VERSION "0.2"

NS_ :

BS_ :

BU_ : BMS_LV DIAG_TOOL SB_FRONT TLB_BAT TPMS IMU DASH DSPACE EXTRA_NODE SB_REAR SCANNER

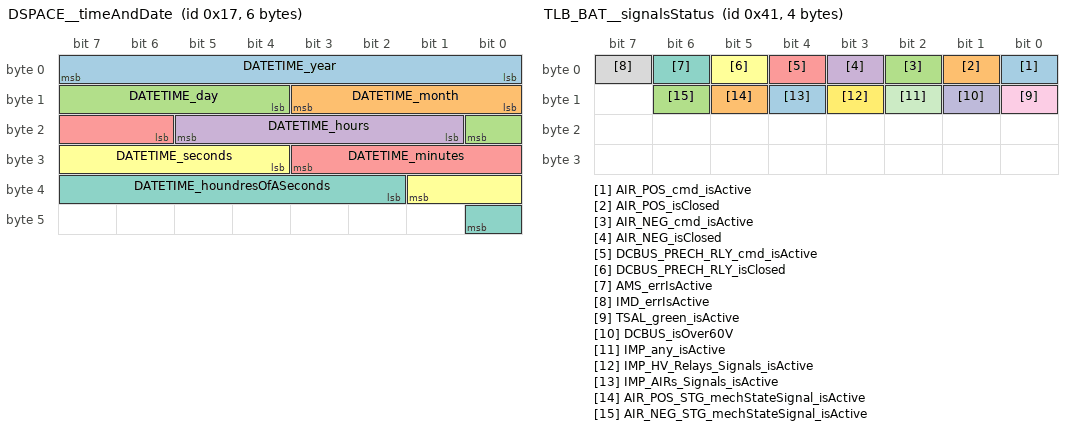
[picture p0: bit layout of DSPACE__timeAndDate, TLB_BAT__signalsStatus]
BO_ 23 DSPACE__timeAndDate: 6 DSPACE
	SG_ DATETIME_year : 0|8@1+ (1,0) [0|255] "" DASH,SB_FRONT,SB_REAR,SCANNER,TLB_BAT,BMS_LV
	SG_ DATETIME_month : 8|4@1+ (1,0) [0|11] "" DASH,SB_FRONT,SB_REAR,SCANNER,TLB_BAT,BMS_LV
	SG_ DATETIME_day : 12|5@1+ (1,0) [1|31] "" DASH,SB_FRONT,SB_REAR,SCANNER,TLB_BAT,BMS_LV
	SG_ DATETIME_hours : 17|5@1+ (1,0) [0|23] "h" DASH,SB_FRONT,SB_REAR,SCANNER,TLB_BAT,BMS_LV
	SG_ DATETIME_minutes : 22|6@1+ (1,0) [0|59] "min" DASH,SB_FRONT,SB_REAR,SCANNER,TLB_BAT,BMS_LV
	SG_ DATETIME_seconds : 28|6@1+ (1,0) [0|59] "sec" DASH,SB_FRONT,SB_REAR,SCANNER,TLB_BAT,BMS_LV
	SG_ DATETIME_houndresOfASeconds : 34|7@1+ (1,0) [0|99] "sec" DASH,SB_FRONT,SB_REAR,SCANNER,TLB_BAT,BMS_LV

BO_ 65 TLB_BAT__signalsStatus: 4 TLB_BAT
	SG_ AIR_POS_cmd_isActive : 0|1@1+ (1,0) [0|1] "" DSPACE,SCANNER
	SG_ AIR_POS_isClosed : 1|1@1+ (1,0) [0|1] "" DSPACE,SCANNER
	SG_ AIR_NEG_cmd_isActive : 2|1@1+ (1,0) [0|1] "" DSPACE,SCANNER
	SG_ AIR_NEG_isClosed : 3|1@1+ (1,0) [0|1] "" DSPACE,SCANNER
	SG_ DCBUS_PRECH_RLY_cmd_isActive : 4|1@1+ (1,0) [0|1] "" DSPACE,SCANNER
	SG_ DCBUS_PRECH_RLY_isClosed : 5|1@1+ (1,0) [0|1] "" DSPACE,SCANNER
	SG_ AMS_errIsActive : 6|1@1+ (1,0) [0|1] "" DSPACE,SCANNER
	SG_ IMD_errIsActive : 7|1@1+ (1,0) [0|1] "" DSPACE,SCANNER
	SG_ TSAL_green_isActive : 8|1@1+ (1,0) [0|1] "" DSPACE,SCANNER
	SG_ DCBUS_isOver60V : 9|1@1+ (1,0) [0|1] "" DSPACE,SCANNER
	SG_ IMP_any_isActive : 10|1@1+ (1,0) [0|1] "" DSPACE,SCANNER
	SG_ IMP_HV_Relays_Signals_isActive : 11|1@1+ (1,0) [0|1] "" DSPACE,SCANNER
	SG_ IMP_AIRs_Signals_isActive : 12|1@1+ (1,0) [0|1] "" DSPACE,SCANNER
	SG_ AIR_POS_STG_mechStateSignal_isActive : 13|1@1+ (1,0) [0|1] "" DSPACE,SCANNER
	SG_ AIR_NEG_STG_mechStateSignal_isActive : 14|1@1+ (1,0) [0|1] "" DSPACE,SCANNER

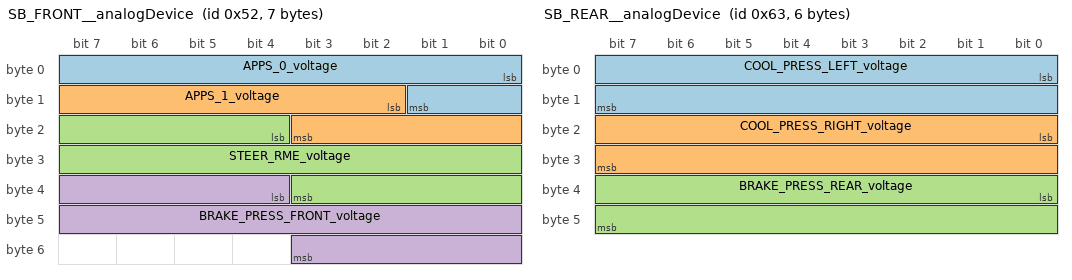
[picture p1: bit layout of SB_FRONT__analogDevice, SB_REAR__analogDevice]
BO_ 82 SB_FRONT__analogDevice: 7 SB_FRONT
	SG_ APPS_0_voltage : 0|10@1+ (1,0) [0|65535] "mV" DSPACE,SCANNER
	SG_ APPS_1_voltage : 10|10@1+ (1,0) [0|65535] "mV" DSPACE,SCANNER
	SG_ STEER_RME_voltage : 20|16@1+ (1,0) [0|65535] "mV" DSPACE,SCANNER
	SG_ BRAKE_PRESS_FRONT_voltage : 36|16@1+ (1,0) [0|65535] "mV" DSPACE,SCANNER

BO_ 99 SB_REAR__analogDevice: 6 SB_REAR
	SG_ COOL_PRESS_LEFT_voltage : 0|16@1+ (1,0) [0|65535] "mV" DSPACE,SCANNER
	SG_ COOL_PRESS_RIGHT_voltage : 16|16@1+ (1,0) [0|65535] "mV" DSPACE,SCANNER
	SG_ BRAKE_PRESS_REAR_voltage : 32|16@1+ (1,0) [0|65535] "mV" DSPACE,SCANNER

BO_ 115 SB_REAR__criticalPeripherals: 1 SB_REAR
	SG_ DISCHARGE_isOpen : 0|1@1+ (1,0) [0|1] "" DSPACE,SCANNER
	SG_ BSPD_hasError : 1|1@1+ (1,0) [0|1] "" DSPACE,SCANNER

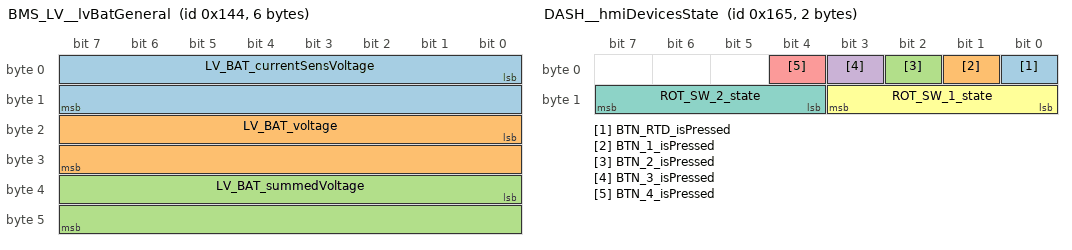
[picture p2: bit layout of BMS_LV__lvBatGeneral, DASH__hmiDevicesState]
BO_ 324 BMS_LV__lvBatGeneral: 6 BMS_LV
	SG_ LV_BAT_currentSensVoltage : 0|16@1+ (0.076,0) [0|4980.66] "mV" DSPACE,SCANNER
	SG_ LV_BAT_voltage : 16|16@1+ (0.267,14000) [0|17497.845] "mV" DSPACE,SCANNER
	SG_ LV_BAT_summedVoltage : 32|16@1+ (0.267,14000) [0|17497.845] "mV" DSPACE,SCANNER

BO_ 357 DASH__hmiDevicesState: 2 DASH
	SG_ BTN_RTD_isPressed : 0|1@1+ (1,0) [0|255] "" DSPACE,SCANNER
	SG_ BTN_1_isPressed : 1|1@1+ (1,0) [0|1] "" DSPACE,SCANNER
	SG_ BTN_2_isPressed : 2|1@1+ (1,0) [0|1] "" DSPACE,SCANNER
	SG_ BTN_3_isPressed : 3|1@1+ (1,0) [0|1] "" DSPACE,SCANNER
	SG_ BTN_4_isPressed : 4|1@1+ (1,0) [0|1] "" DSPACE,SCANNER
	SG_ ROT_SW_1_state : 8|4@1+ (1,0) [0|9] "" DSPACE,SCANNER
	SG_ ROT_SW_2_state : 12|4@1+ (1,0) [0|9] "" DSPACE,SCANNER

BO_ 388 SBG_ECAN_MSG_GPS2_POS_INFO: 8 IMU
	SG_ TIME_STAMP : 0|32@1+ (1,0) [0|4294970000] "usec" SCANNER
	SG_ STATUS : 32|32@1+ (1,0) [0|4294970000] "" SCANNER

BO_ 389 SBG_ECAN_MSG_GPS2_POS: 8 IMU
	SG_ LATITUDE : 0|32@1- (0.0000001,0) [-214.7483648|214.7483647] "deg" SCANNER
	SG_ LONGITUDE : 32|32@1- (0.0000001,0) [-214.7483648|214.7483647] "deg" SCANNER

BO_ 392 SBG_ECAN_MSG_GPS2_HDT_INFO: 6 IMU
	SG_ TIME_STAMP : 0|32@1+ (1,0) [0|4294970000] "usec" SCANNER
	SG_ STATUS : 32|16@1+ (1,0) [0|65535] "" SCANNER

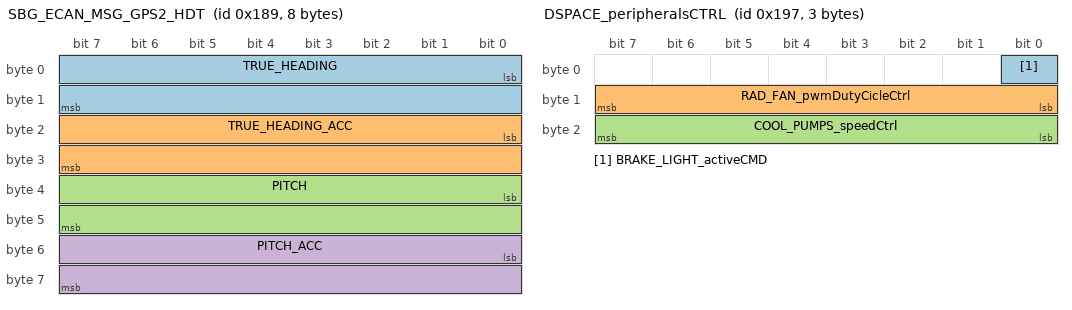
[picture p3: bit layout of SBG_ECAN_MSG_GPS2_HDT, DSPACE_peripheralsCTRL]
BO_ 393 SBG_ECAN_MSG_GPS2_HDT: 8 IMU
	SG_ TRUE_HEADING : 0|16@1+ (0.01,0) [0|655.35] "deg" SCANNER
	SG_ TRUE_HEADING_ACC : 16|16@1+ (0.01,0) [0|655.35] "deg" SCANNER
	SG_ PITCH : 32|16@1- (0.01,0) [-327.68|327.67] "deg" SCANNER
	SG_ PITCH_ACC : 48|16@1+ (0.01,0) [0|655.35] "deg" SCANNER

BO_ 407 DSPACE_peripheralsCTRL: 3 DSPACE
	SG_ BRAKE_LIGHT_activeCMD : 0|1@1+ (1,0) [0|1] "" DASH,SB_REAR,SCANNER
	SG_ RAD_FAN_pwmDutyCicleCtrl : 8|8@1+ (1,0) [0|100] "%" DASH,SB_REAR,SCANNER
	SG_ COOL_PUMPS_speedCtrl : 16|8@1+ (1,0) [0|100] "%" DASH,SB_REAR,SCANNER

BO_ 512 SBG_ECAN_MSG_EVENT_INFO_A: 8 IMU
	SG_ TIME_STAMP : 0|32@1+ (1,0) [0|4294970000] "usec" Vector__XXX
	SG_ STATUS : 32|16@1+ (1,0) [0|65535] "" Vector__XXX

BO_ 646 DIAG_TOOL__xcpTxBMS_LV: 8 DIAG_TOOL
	SG_ xcp_payload : 0|64@1+ (1,0) [0|0] "" BMS_LV

BO_ 662 DIAG_TOOL__xcpTxDASH: 8 DIAG_TOOL
	SG_ xcp_payload : 0|64@1+ (1,0) [0|0] "" DASH

BO_ 678 DIAG_TOOL__xcpTxSB_REAR: 8 DIAG_TOOL
	SG_ xcp_payload : 0|64@1+ (1,0) [0|0] "" SB_REAR

BO_ 694 DIAG_TOOL__xcpTxSB_FRONT: 8 DIAG_TOOL
	SG_ xcp_payload : 0|64@1+ (1,0) [0|0] "" SB_FRONT

BO_ 710 DIAG_TOOL__xcpTxSCANNER: 8 DIAG_TOOL
	SG_ xcp_payload : 0|64@1+ (1,0) [0|0] "" SCANNER

BO_ 726 DIAG_TOOL__xcpTxTLB_BAT: 8 DIAG_TOOL
	SG_ xcp_payload : 0|64@1+ (1,0) [0|0] "" TLB_BAT

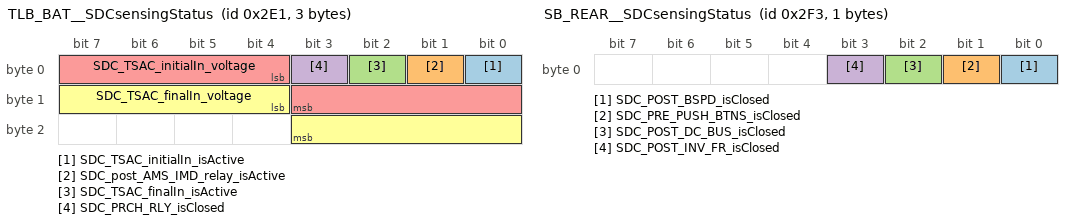
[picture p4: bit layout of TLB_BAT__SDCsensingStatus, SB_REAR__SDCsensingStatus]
BO_ 737 TLB_BAT__SDCsensingStatus: 3 TLB_BAT
	SG_ SDC_TSAC_initialIn_isActive : 0|1@1+ (1,0) [0|1] "" DSPACE,SCANNER
	SG_ SDC_post_AMS_IMD_relay_isActive : 1|1@1+ (1,0) [0|1] "" DSPACE,SCANNER
	SG_ SDC_TSAC_finalIn_isActive : 2|1@1+ (1,0) [0|1] "" DSPACE,SCANNER
	SG_ SDC_PRCH_RLY_isClosed : 3|1@1+ (1,0) [0|1] "" DSPACE,SCANNER
	SG_ SDC_TSAC_initialIn_voltage : 4|8@1+ (0.177,0) [0|255] "V" DSPACE,SCANNER
	SG_ SDC_TSAC_finalIn_voltage : 12|8@1+ (0.177,0) [0|255] "V" DSPACE,SCANNER

BO_ 755 SB_REAR__SDCsensingStatus: 1 SB_REAR
	SG_ SDC_POST_BSPD_isClosed : 0|1@1+ (1,0) [0|1] "" DSPACE,SCANNER
	SG_ SDC_PRE_PUSH_BTNS_isClosed : 1|1@1+ (1,0) [0|1] "" DSPACE,SCANNER
	SG_ SDC_POST_DC_BUS_isClosed : 2|1@1+ (1,0) [0|1] "" DSPACE,SCANNER
	SG_ SDC_POST_INV_FR_isClosed : 3|1@1+ (1,0) [0|1] "" DSPACE,SCANNER

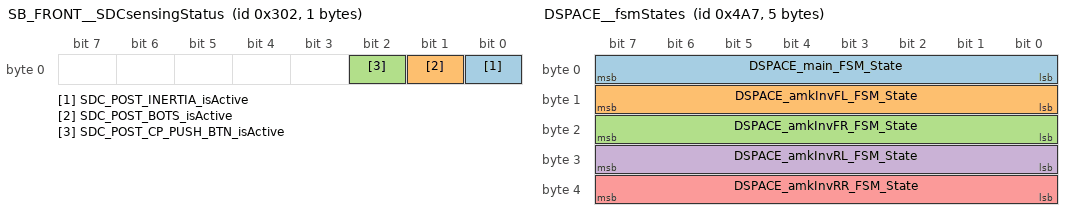
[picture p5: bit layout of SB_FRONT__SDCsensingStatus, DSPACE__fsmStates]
BO_ 770 SB_FRONT__SDCsensingStatus: 1 SB_FRONT
	SG_ SDC_POST_INERTIA_isActive : 0|1@1+ (1,0) [0|1] "" DSPACE,SCANNER
	SG_ SDC_POST_BOTS_isActive : 1|1@1+ (1,0) [0|1] "" DSPACE,SCANNER
	SG_ SDC_POST_CP_PUSH_BTN_isActive : 2|1@1+ (1,0) [0|1] "" DSPACE,SCANNER

BO_ 802 SB_FRONT__potentiometer: 4 SB_FRONT
	SG_ LPPS_DAMPER_FL_voltage : 0|16@1+ (1,0) [0|65535] "mV" DSPACE,SCANNER
	SG_ LPPS_DAMPER_FR_voltage : 16|16@1+ (1,0) [0|65535] "mV" DSPACE,SCANNER

BO_ 819 SB_REAR__potentiometer: 4 SB_REAR
	SG_ LPPS_DAMPER_RL_voltage : 0|16@1+ (1,0) [0|65535] "mV" DSPACE,SCANNER
	SG_ LPPS_DAMPER_RR_voltage : 16|16@1+ (1,0) [0|65535] "mV" DSPACE,SCANNER

BO_ 1121 TLB_BAT__xcpTx: 8 TLB_BAT
	SG_ xcp_payload : 0|64@1+ (1,0) [0|0] "" DIAG_TOOL

BO_ 1122 SB_FRONT__xcpTx: 8 SB_FRONT
	SG_ xcp_payload : 0|64@1+ (1,0) [0|0] "" DIAG_TOOL

BO_ 1123 SB_REAR__xcpTx: 8 SB_REAR
	SG_ xcp_payload : 0|64@1+ (1,0) [0|0] "" DIAG_TOOL

BO_ 1124 BMS_LV__xcpTx: 8 BMS_LV
	SG_ xcp_payload : 0|64@1+ (1,0) [0|0] "" DIAG_TOOL

BO_ 1125 DASH__xcpTx: 8 DASH
	SG_ xcp_payload : 0|64@1+ (1,0) [0|0] "" DIAG_TOOL

BO_ 1129 SCANNER__xcpTx: 8 SCANNER
	SG_ xcp_payload : 0|64@1+ (1,0) [0|0] "" DIAG_TOOL

BO_ 1175 DSPACE__signals: 1 DSPACE
	SG_ HVBAT_soc : 0|8@1+ (1,0) [100|0] "%" DASH,SCANNER

BO_ 1191 DSPACE__fsmStates: 5 DSPACE
	SG_ DSPACE_main_FSM_State : 0|8@1- (1,0) [-1|5] "" DASH,SCANNER
	SG_ DSPACE_amkInvFL_FSM_State : 8|8@1- (1,0) [0|6] "" DASH,SCANNER
	SG_ DSPACE_amkInvFR_FSM_State : 16|8@1- (1,0) [0|6] "" DASH,SCANNER
	SG_ DSPACE_amkInvRL_FSM_State : 24|8@1- (1,0) [0|6] "" DASH,SCANNER
	SG_ DSPACE_amkInvRR_FSM_State : 32|8@1- (1,0) [0|6] "" DASH,SCANNER

BO_ 1204 BMS_LV__cellsStatus: 5 BMS_LV
	SG_ LV_CELL_0_isOV : 0|1@1+ (1,0) [0|1] "" DSPACE,SCANNER
	SG_ LV_CELL_0_isUV : 1|1@1+ (1,0) [0|1] "" DSPACE,SCANNER
	SG_ LV_CELL_1_isOV : 2|1@1+ (1,0) [0|1] "" DSPACE,SCANNER
	SG_ LV_CELL_1_isUV : 3|1@1+ (1,0) [0|1] "" DSPACE,SCANNER
	SG_ LV_CELL_2_isOV : 4|1@1+ (1,0) [0|1] "" DSPACE,SCANNER
	SG_ LV_CELL_2_isUV : 5|1@1+ (1,0) [0|1] "" DSPACE,SCANNER
	SG_ LV_CELL_3_isOV : 6|1@1+ (1,0) [0|1] "" DSPACE,SCANNER
	SG_ LV_CELL_3_isUV : 7|1@1+ (1,0) [0|1] "" DSPACE,SCANNER
	SG_ LV_CELL_4_isOV : 8|1@1+ (1,0) [0|1] "" DSPACE,SCANNER
	SG_ LV_CELL_4_isUV : 9|1@1+ (1,0) [0|1] "" DSPACE,SCANNER
	SG_ LV_CELL_5_isOV : 10|1@1+ (1,0) [0|1] "" DSPACE,SCANNER
	SG_ LV_CELL_5_isUV : 11|1@1+ (1,0) [0|1] "" DSPACE,SCANNER
	SG_ LV_CELL_6_isOV : 12|1@1+ (1,0) [0|1] "" DSPACE,SCANNER
	SG_ LV_CELL_6_isUV : 13|1@1+ (1,0) [0|1] "" DSPACE,SCANNER
	SG_ LV_CELL_NTC_00_isOT : 14|1@1+ (1,0) [0|1] "" DSPACE,SCANNER
	SG_ LV_CELL_NTC_01_isOT : 15|1@1+ (1,0) [0|1] "" DSPACE,SCANNER
	SG_ LV_CELL_NTC_02_isOT : 16|1@1+ (1,0) [0|1] "" DSPACE,SCANNER
	SG_ LV_CELL_NTC_03_isOT : 17|1@1+ (1,0) [0|1] "" DSPACE,SCANNER
	SG_ LV_CELL_NTC_04_isOT : 18|1@1+ (1,0) [0|1] "" DSPACE,SCANNER
	SG_ LV_CELL_NTC_05_isOT : 19|1@1+ (1,0) [0|1] "" DSPACE,SCANNER
	SG_ LV_CELL_NTC_06_isOT : 20|1@1+ (1,0) [0|1] "" DSPACE,SCANNER
	SG_ LV_CELL_NTC_07_isOT : 21|1@1+ (1,0) [0|1] "" DSPACE,SCANNER
	SG_ LV_CELL_NTC_08_isOT : 22|1@1+ (1,0) [0|1] "" DSPACE,SCANNER
	SG_ LV_CELL_NTC_09_isOT : 23|1@1+ (1,0) [0|1] "" DSPACE,SCANNER
	SG_ LV_CELL_NTC_10_isOT : 24|1@1+ (1,0) [0|1] "" DSPACE,SCANNER
	SG_ LV_CELL_NTC_11_isOT : 25|1@1+ (1,0) [0|1] "" DSPACE,SCANNER

BO_ 1220 BMS_LV__status: 1 BMS_LV
	SG_ LV_RELAY_isClosed : 0|1@1+ (1,0) [0|1] "" DSPACE,SCANNER
	SG_ LV_RELAY_isRelayOverrideOn : 1|1@1+ (1,0) [0|1] "" DSPACE,SCANNER

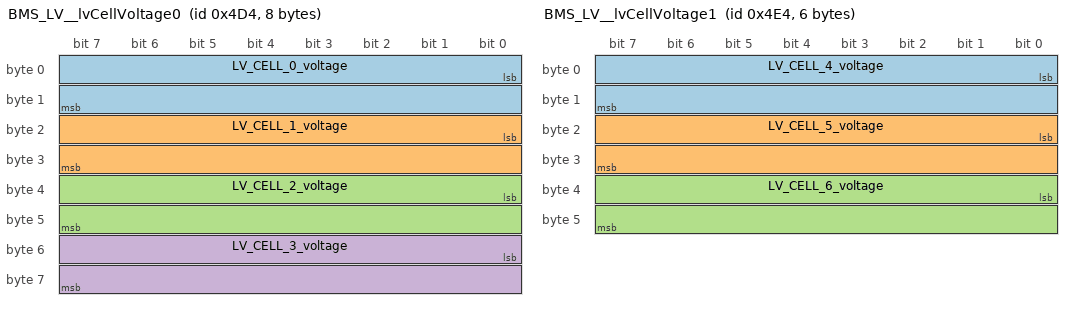
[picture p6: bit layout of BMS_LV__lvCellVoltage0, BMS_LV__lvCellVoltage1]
BO_ 1236 BMS_LV__lvCellVoltage0: 8 BMS_LV
	SG_ LV_CELL_0_voltage : 0|16@1+ (0.038,2000) [0|2490.33] "mV" DSPACE,SCANNER
	SG_ LV_CELL_1_voltage : 16|16@1+ (0.038,2000) [0|2490.33] "mV" DSPACE,SCANNER
	SG_ LV_CELL_2_voltage : 32|16@1+ (0.038,2000) [0|2490.33] "mV" DSPACE,SCANNER
	SG_ LV_CELL_3_voltage : 48|16@1+ (0.038,2000) [0|2490.33] "mV" DSPACE,SCANNER

BO_ 1252 BMS_LV__lvCellVoltage1: 6 BMS_LV
	SG_ LV_CELL_4_voltage : 0|16@1+ (0.038,2000) [0|2490.33] "mV" DSPACE,SCANNER
	SG_ LV_CELL_5_voltage : 16|16@1+ (0.038,2000) [0|2490.33] "mV" DSPACE,SCANNER
	SG_ LV_CELL_6_voltage : 32|16@1+ (0.038,2000) [0|2490.33] "mV" DSPACE,SCANNER

BO_ 1269 DASH__peripheralsStatus: 1 DASH
	SG_ TSAC_FAN_pwmDutyCycleStatus : 0|4@1+ (1,0) [0|10] "%" DSPACE,SCANNER

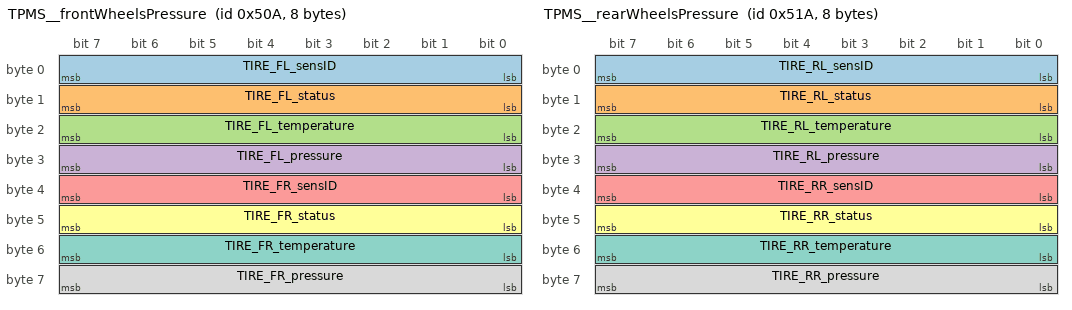
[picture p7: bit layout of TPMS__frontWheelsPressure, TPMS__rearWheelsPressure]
BO_ 1290 TPMS__frontWheelsPressure: 8 TPMS
	SG_ TIRE_FL_sensID : 0|8@1+ (1,0) [0|255] "" DSPACE,SCANNER
	SG_ TIRE_FL_status : 8|8@1+ (1,0) [0|255] "" DSPACE,SCANNER
	SG_ TIRE_FL_temperature : 16|8@1+ (1,0) [10|170] "degC" DSPACE,SCANNER
	SG_ TIRE_FL_pressure : 24|8@1+ (1,0) [1|254] "mB" DSPACE,SCANNER
	SG_ TIRE_FR_sensID : 32|8@1+ (1,0) [0|255] "" DSPACE,SCANNER
	SG_ TIRE_FR_status : 40|8@1+ (1,0) [0|255] "" DSPACE,SCANNER
	SG_ TIRE_FR_temperature : 48|8@1+ (1,0) [10|170] "degC" DSPACE,SCANNER
	SG_ TIRE_FR_pressure : 56|8@1+ (1,0) [1|254] "mB" DSPACE,SCANNER

BO_ 1306 TPMS__rearWheelsPressure: 8 TPMS
	SG_ TIRE_RL_sensID : 0|8@1+ (1,0) [0|255] "" DSPACE,SCANNER
	SG_ TIRE_RL_status : 8|8@1+ (1,0) [0|255] "" DSPACE,SCANNER
	SG_ TIRE_RL_temperature : 16|8@1+ (1,0) [10|170] "degC" DSPACE,SCANNER
	SG_ TIRE_RL_pressure : 24|8@1+ (1,0) [1|254] "mB" DSPACE,SCANNER
	SG_ TIRE_RR_sensID : 32|8@1+ (1,0) [0|255] "" DSPACE,SCANNER
	SG_ TIRE_RR_status : 40|8@1+ (1,0) [0|255] "" DSPACE,SCANNER
	SG_ TIRE_RR_temperature : 48|8@1+ (1,0) [10|170] "degC" DSPACE,SCANNER
	SG_ TIRE_RR_pressure : 56|8@1+ (1,0) [1|254] "mB" DSPACE,SCANNER

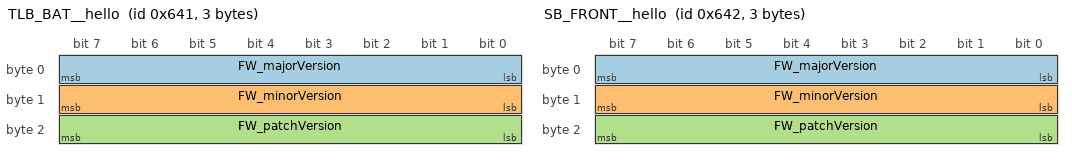
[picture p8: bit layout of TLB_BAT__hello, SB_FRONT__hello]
BO_ 1601 TLB_BAT__hello: 3 TLB_BAT
	SG_ FW_majorVersion : 0|8@1+ (1,0) [0|255] "" DSPACE,SCANNER
	SG_ FW_minorVersion : 8|8@1+ (1,0) [0|255] "" DSPACE,SCANNER
	SG_ FW_patchVersion : 16|8@1+ (1,0) [0|255] "" DSPACE,SCANNER

BO_ 1602 SB_FRONT__hello: 3 SB_FRONT
	SG_ FW_majorVersion : 0|8@1+ (1,0) [0|255] "" DSPACE,SCANNER
	SG_ FW_minorVersion : 8|8@1+ (1,0) [0|255] "" DSPACE,SCANNER
	SG_ FW_patchVersion : 16|8@1+ (1,0) [0|255] "" DSPACE,SCANNER

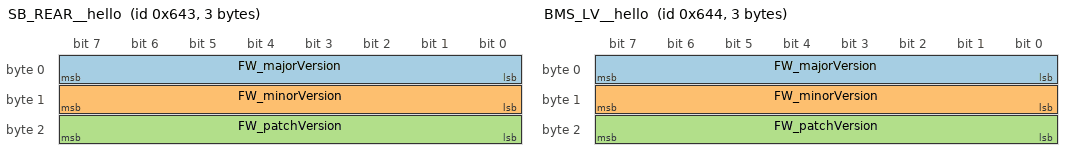
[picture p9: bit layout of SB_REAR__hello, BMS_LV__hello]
BO_ 1603 SB_REAR__hello: 3 SB_REAR
	SG_ FW_majorVersion : 0|8@1+ (1,0) [0|255] "" DSPACE,SCANNER
	SG_ FW_minorVersion : 8|8@1+ (1,0) [0|255] "" DSPACE,SCANNER
	SG_ FW_patchVersion : 16|8@1+ (1,0) [0|255] "" DSPACE,SCANNER

BO_ 1604 BMS_LV__hello: 3 BMS_LV
	SG_ FW_majorVersion : 0|8@1+ (1,0) [0|255] "" DSPACE,SCANNER
	SG_ FW_minorVersion : 8|8@1+ (1,0) [0|255] "" DSPACE,SCANNER
	SG_ FW_patchVersion : 16|8@1+ (1,0) [0|255] "" DSPACE,SCANNER

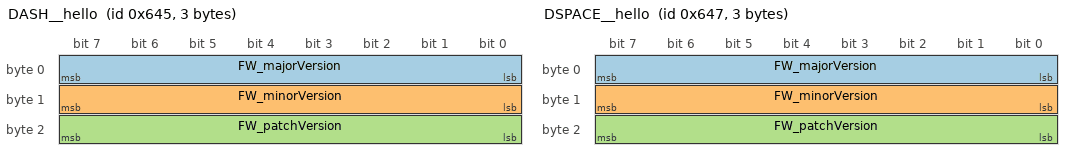
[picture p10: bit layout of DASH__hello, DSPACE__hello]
BO_ 1605 DASH__hello: 3 DASH
	SG_ FW_majorVersion : 0|8@1+ (1,0) [0|255] "" DSPACE,SCANNER
	SG_ FW_minorVersion : 8|8@1+ (1,0) [0|255] "" DSPACE,SCANNER
	SG_ FW_patchVersion : 16|8@1+ (1,0) [0|255] "" DSPACE,SCANNER

BO_ 1607 DSPACE__hello: 3 DSPACE
	SG_ FW_majorVersion : 0|8@1+ (1,0) [0|255] "" SCANNER
	SG_ FW_minorVersion : 8|8@1+ (1,0) [0|255] "" SCANNER
	SG_ FW_patchVersion : 16|8@1+ (1,0) [0|255] "" SCANNER

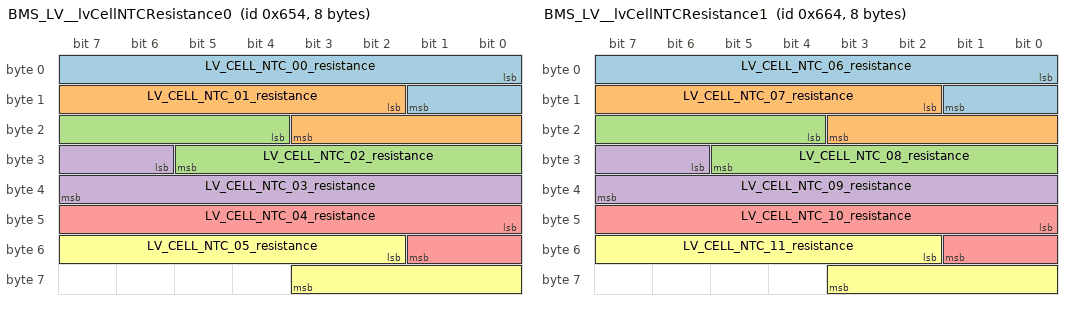
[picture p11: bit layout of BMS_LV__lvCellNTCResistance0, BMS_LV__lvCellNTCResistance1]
BO_ 1620 BMS_LV__lvCellNTCResistance0: 8 BMS_LV
	SG_ LV_CELL_NTC_00_resistance : 0|10@1+ (31.25,1000) [0|31968.75] "Ohm" DSPACE,SCANNER
	SG_ LV_CELL_NTC_01_resistance : 10|10@1+ (31.25,1000) [0|31968.75] "Ohm" DSPACE,SCANNER
	SG_ LV_CELL_NTC_02_resistance : 20|10@1+ (31.25,1000) [0|31968.75] "Ohm" DSPACE,SCANNER
	SG_ LV_CELL_NTC_03_resistance : 30|10@1+ (31.25,1000) [0|31968.75] "Ohm" DSPACE,SCANNER
	SG_ LV_CELL_NTC_04_resistance : 40|10@1+ (31.25,1000) [0|31968.75] "Ohm" DSPACE,SCANNER
	SG_ LV_CELL_NTC_05_resistance : 50|10@1+ (31.25,1000) [0|31968.75] "Ohm" DSPACE,SCANNER

BO_ 1636 BMS_LV__lvCellNTCResistance1: 8 BMS_LV
	SG_ LV_CELL_NTC_06_resistance : 0|10@1+ (31.25,1000) [0|31968.75] "Ohm" DSPACE,SCANNER
	SG_ LV_CELL_NTC_07_resistance : 10|10@1+ (31.25,1000) [0|31968.75] "Ohm" DSPACE,SCANNER
	SG_ LV_CELL_NTC_08_resistance : 20|10@1+ (31.25,1000) [0|31968.75] "Ohm" DSPACE,SCANNER
	SG_ LV_CELL_NTC_09_resistance : 30|10@1+ (31.25,1000) [0|31968.75] "Ohm" DSPACE,SCANNER
	SG_ LV_CELL_NTC_10_resistance : 40|10@1+ (31.25,1000) [0|31968.75] "Ohm" DSPACE,SCANNER
	SG_ LV_CELL_NTC_11_resistance : 50|10@1+ (31.25,1000) [0|31968.75] "Ohm" DSPACE,SCANNER

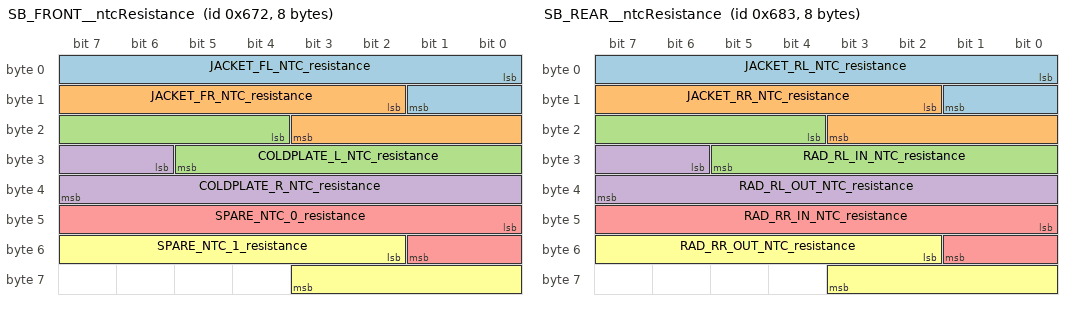
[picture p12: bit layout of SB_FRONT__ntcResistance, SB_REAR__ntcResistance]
BO_ 1650 SB_FRONT__ntcResistance: 8 SB_FRONT
	SG_ JACKET_FL_NTC_resistance : 0|10@1+ (31.25,1000) [0|31968.75] "Ohm" DSPACE,SCANNER
	SG_ JACKET_FR_NTC_resistance : 10|10@1+ (31.25,1000) [0|31968.75] "Ohm" DSPACE,SCANNER
	SG_ COLDPLATE_L_NTC_resistance : 20|10@1+ (31.25,1000) [0|31968.75] "Ohm" DSPACE,SCANNER
	SG_ COLDPLATE_R_NTC_resistance : 30|10@1+ (31.25,1000) [0|31968.75] "Ohm" DSPACE,SCANNER
	SG_ SPARE_NTC_0_resistance : 40|10@1+ (31.25,1000) [0|31968.75] "Ohm" DSPACE,SCANNER
	SG_ SPARE_NTC_1_resistance : 50|10@1+ (31.25,1000) [0|31968.75] "Ohm" DSPACE,SCANNER

BO_ 1667 SB_REAR__ntcResistance: 8 SB_REAR
	SG_ JACKET_RL_NTC_resistance : 0|10@1+ (31.25,1000) [0|31968.75] "Ohm" DSPACE,SCANNER
	SG_ JACKET_RR_NTC_resistance : 10|10@1+ (31.25,1000) [0|31968.75] "Ohm" DSPACE,SCANNER
	SG_ RAD_RL_IN_NTC_resistance : 20|10@1+ (31.25,1000) [0|31968.75] "Ohm" DSPACE,SCANNER
	SG_ RAD_RL_OUT_NTC_resistance : 30|10@1+ (31.25,1000) [0|31968.75] "Ohm" DSPACE,SCANNER
	SG_ RAD_RR_IN_NTC_resistance : 40|10@1+ (31.25,1000) [0|31968.75] "Ohm" DSPACE,SCANNER
	SG_ RAD_RR_OUT_NTC_resistance : 50|10@1+ (31.25,1000) [0|31968.75] "Ohm" DSPACE,SCANNER

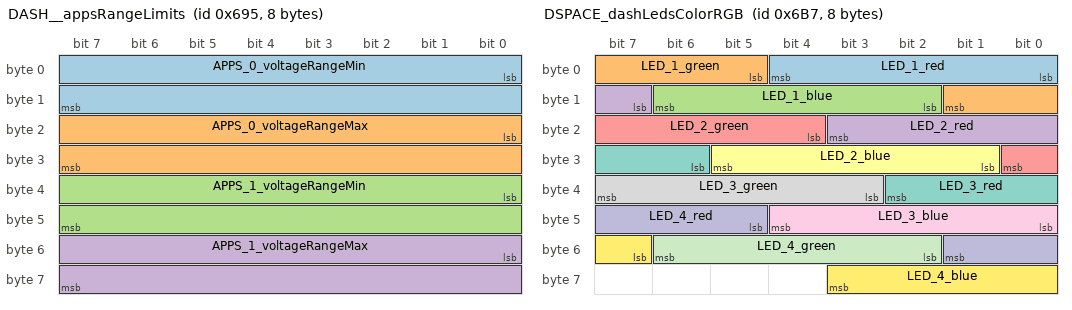
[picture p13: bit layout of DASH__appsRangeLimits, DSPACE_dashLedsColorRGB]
BO_ 1685 DASH__appsRangeLimits: 8 DASH
	SG_ APPS_0_voltageRangeMin : 0|16@1+ (1,0) [0|65535] "mV" DSPACE,SCANNER
	SG_ APPS_0_voltageRangeMax : 16|16@1+ (1,0) [0|65535] "mV" DSPACE,SCANNER
	SG_ APPS_1_voltageRangeMin : 32|16@1+ (1,0) [0|65535] "mV" DSPACE,SCANNER
	SG_ APPS_1_voltageRangeMax : 48|16@1+ (1,0) [0|65535] "mV" DSPACE,SCANNER

BO_ 1701 DASH__carCommands: 2 DASH
	SG_ BMS_LV_diagPWD : 0|15@1+ (1,0) [0|32768] "" BMS_LV
	SG_ LV_RELAY_forcedState : 15|1@1+ (1,0) [0|1] "closed" BMS_LV

BO_ 1719 DSPACE_dashLedsColorRGB: 8 DSPACE
	SG_ LED_1_red : 0|5@1+ (1,0) [0|31] "" Vector__XXX
	SG_ LED_1_green : 5|5@1+ (1,0) [0|31] "" Vector__XXX
	SG_ LED_1_blue : 10|5@1+ (1,0) [0|31] "" Vector__XXX
	SG_ LED_2_red : 15|5@1+ (1,0) [0|31] "" Vector__XXX
	SG_ LED_2_green : 20|5@1+ (1,0) [0|31] "" Vector__XXX
	SG_ LED_2_blue : 25|5@1+ (1,0) [0|31] "" Vector__XXX
	SG_ LED_3_red : 30|5@1+ (1,0) [0|31] "" Vector__XXX
	SG_ LED_3_green : 35|5@1+ (1,0) [0|31] "" Vector__XXX
	SG_ LED_3_blue : 40|5@1+ (1,0) [0|31] "" Vector__XXX
	SG_ LED_4_red : 45|5@1+ (1,0) [0|31] "" Vector__XXX
	SG_ LED_4_green : 50|5@1+ (1,0) [0|31] "" Vector__XXX
	SG_ LED_4_blue : 55|5@1+ (1,0) [0|31] "" Vector__XXX

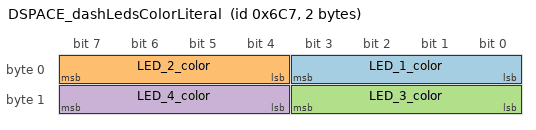
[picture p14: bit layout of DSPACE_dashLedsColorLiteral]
BO_ 1735 DSPACE_dashLedsColorLiteral: 2 DSPACE
	SG_ LED_1_color : 0|4@1+ (1,0) [0|8] "" Vector__XXX
	SG_ LED_2_color : 4|4@1+ (1,0) [0|8] "" Vector__XXX
	SG_ LED_3_color : 8|4@1+ (1,0) [0|8] "" Vector__XXX
	SG_ LED_4_color : 12|4@1+ (1,0) [0|8] "" Vector__XXX

BO_ 1800 IRTS_placeholderMessage: 8 EXTRA_NODE
	SG_ IRTS_signalPlaceholder : 0|64@1+ (1,0) [0|65535] "" Vector__XXX

CM_ BU_ SB_FRONT "Sensorboard front ECU.";
CM_ BU_ TLB_BAT "TSAL-latch-board battery ECU.";
CM_ BU_ TPMS "Tire pressure monitoring system.";
CM_ BU_ IMU "Inertial Measurement Unit.";
CM_ BU_ BMS_LV "Battery-Management-System Low-Voltage ECU.";
CM_ BU_ DIAG_TOOL "Diagnostic tool.";
CM_ BU_ EXTRA_NODE "Extra CAN BUS-Nodes not permanent or temporary";
CM_ BU_ SB_REAR "Sensorboard rear ECU.";
CM_ BU_ SCANNER "Can Logger ECU";
CM_ BU_ DASH "Dashboard ECU.";
CM_ BU_ DSPACE "An automotive ECU.";
CM_ BO_ 678 "(send_type: CyclicIfActive)";
CM_ SG_ 678 xcp_payload "xcp payload data";
CM_ BO_ 1701 "(send_type: IfActive)";
CM_ SG_ 1701 BMS_LV_diagPWD "The password to enter diagnostic mode of the BMS_LV.";
CM_ SG_ 1701 LV_RELAY_forcedState "The command to force the LV relay open (0) or closed (1).";
CM_ BO_ 115 "(cycle_time: 10) (send_type: Cyclic)";
CM_ SG_ 115 DISCHARGE_isOpen "States whether the discharge is open.";
CM_ SG_ 115 BSPD_hasError "States whether the BSPD has an error.";
CM_ BO_ 1124 "(send_type: CyclicIfActive)";
CM_ SG_ 1124 xcp_payload "xcp payload data";
CM_ BO_ 23 "(cycle_time: 10) (send_type: Cyclic)";
CM_ SG_ 23 DATETIME_year "Current year expressed as an offset from 1970.";
CM_ SG_ 23 DATETIME_month "Current month of the year (1 = January, 12 = December).";
CM_ SG_ 23 DATETIME_day "Current day of the month, from 1 to 31.";
CM_ SG_ 23 DATETIME_hours "Current hours of the day (1-24)";
CM_ SG_ 23 DATETIME_minutes "Current minutes of the hour.";
CM_ SG_ 23 DATETIME_seconds "Current seconds of the minute.";
CM_ SG_ 23 DATETIME_houndresOfASeconds "Current tens of the second.";
CM_ BO_ 1123 "(send_type: CyclicIfActive)";
CM_ SG_ 1123 xcp_payload "xcp payload data";
CM_ BO_ 1605 "(send_type: IfActive)";
CM_ SG_ 1605 FW_majorVersion "firmware major version number";
CM_ SG_ 1605 FW_minorVersion "firmware minor version number";
CM_ SG_ 1605 FW_patchVersion "firmware patch version number";
CM_ BO_ 1191 "(cycle_time: 100) (send_type: Cyclic)";
CM_ SG_ 1191 DSPACE_main_FSM_State "The state of the main/RTD FSM of dspace.";
CM_ SG_ 1191 DSPACE_amkInvFL_FSM_State "The state of the AMK Inverter Front Left FSM of dspace.";
CM_ SG_ 1191 DSPACE_amkInvFR_FSM_State "The state of the AMK Inverter Front Right FSM of dspace.";
CM_ SG_ 1191 DSPACE_amkInvRL_FSM_State "The state of the AMK Inverter Rear Left FSM of dspace.";
CM_ SG_ 1191 DSPACE_amkInvRR_FSM_State "The state of the AMK Inverter Rear Right FSM of dspace.";
CM_ BO_ 1620 "(cycle_time: 2000) (send_type: Cyclic)";
CM_ SG_ 1620 LV_CELL_NTC_05_resistance "The resistance of the NTC #5 in the battery pack expressed in Ohm.";
CM_ SG_ 1620 LV_CELL_NTC_00_resistance "The resistance of the NTC #0 in the battery pack expressed in Ohm.";
CM_ SG_ 1620 LV_CELL_NTC_01_resistance "The resistance of the NTC #1 in the battery pack expressed in Ohm.";
CM_ SG_ 1620 LV_CELL_NTC_02_resistance "The resistance of the NTC #2 in the battery pack expressed in Ohm.";
CM_ SG_ 1620 LV_CELL_NTC_03_resistance "The resistance of the NTC #3 in the battery pack expressed in Ohm.";
CM_ SG_ 1620 LV_CELL_NTC_04_resistance "The resistance of the NTC #4 in the battery pack expressed in Ohm.";
CM_ BO_ 1236 "(cycle_time: 100) (send_type: Cyclic)";
CM_ SG_ 1236 LV_CELL_1_voltage "The voltage of the LV cell #1 expressed in mV.";
CM_ SG_ 1236 LV_CELL_2_voltage "The voltage of the LV cell #2 expressed in mV.";
CM_ SG_ 1236 LV_CELL_3_voltage "The voltage of the LV cell #3 expressed in mV.";
CM_ SG_ 1236 LV_CELL_0_voltage "The voltage of the LV cell #0 expressed in mV.";
CM_ BO_ 1125 "(send_type: CyclicIfActive)";
CM_ SG_ 1125 xcp_payload "xcp payload data";
CM_ BO_ 1601 "(send_type: IfActive)";
CM_ SG_ 1601 FW_majorVersion "firmware major version number";
CM_ SG_ 1601 FW_minorVersion "firmware minor version number";
CM_ SG_ 1601 FW_patchVersion "firmware patch version number";
CM_ BO_ 1252 "(cycle_time: 100) (send_type: Cyclic)";
CM_ SG_ 1252 LV_CELL_6_voltage "The voltage of the LV cell #4 expressed in mV.";
CM_ SG_ 1252 LV_CELL_4_voltage "The voltage of the LV cell #4 expressed in mV.";
CM_ SG_ 1252 LV_CELL_5_voltage "The voltage of the LV cell #4 expressed in mV.";
CM_ BO_ 407 "(cycle_time: 100) (send_type: Cyclic)";
CM_ SG_ 407 COOL_PUMPS_speedCtrl "Speed percentage for Cooling Pumps control.";
CM_ SG_ 407 BRAKE_LIGHT_activeCMD "The command to turn on the brake light (0 inactive - 1 active).";
CM_ SG_ 407 RAD_FAN_pwmDutyCicleCtrl "PWM duty cycle percentage for Radiator Fans control.";
CM_ BO_ 1719 "(cycle_time: 200) (send_type: Cyclic)";
CM_ SG_ 1719 LED_4_green "The green channel of LED #4 of the dashboard.";
CM_ SG_ 1719 LED_1_blue "The blue channel of LED #1 of the dashboard.";
CM_ SG_ 1719 LED_2_red "The red channel of LED #2 of the dashboard.";
CM_ SG_ 1719 LED_2_green "The green channel of LED #2 of the dashboard.";
CM_ SG_ 1719 LED_3_red "The red channel of LED #3 of the dashboard.";
CM_ SG_ 1719 LED_3_blue "The blue channel of LED #3 of the dashboard.";
CM_ SG_ 1719 LED_4_blue "The blue channel of LED #4 of the dashboard.";
CM_ SG_ 1719 LED_1_red "The red channel of LED #1 of the dashboard.";
CM_ SG_ 1719 LED_1_green "The green channel of LED #1 of the dashboard.";
CM_ SG_ 1719 LED_2_blue "The blue channel of LED #2 of the dashboard.";
CM_ SG_ 1719 LED_3_green "The green channel of LED #3 of the dashboard.";
CM_ SG_ 1719 LED_4_red "The red channel of LED #4 of the dashboard.";
CM_ BO_ 662 "(send_type: CyclicIfActive)";
CM_ SG_ 662 xcp_payload "xcp payload data";
CM_ BO_ 1636 "(cycle_time: 2000) (send_type: Cyclic)";
CM_ SG_ 1636 LV_CELL_NTC_07_resistance "The resistance of the NTC #7 in the battery pack expressed in Ohm.";
CM_ SG_ 1636 LV_CELL_NTC_08_resistance "The resistance of the NTC #8 in the battery pack expressed in Ohm.";
CM_ SG_ 1636 LV_CELL_NTC_09_resistance "The resistance of the NTC #9 in the battery pack expressed in Ohm.";
CM_ SG_ 1636 LV_CELL_NTC_10_resistance "The resistance of the NTC #10 in the battery pack expressed in Ohm.";
CM_ SG_ 1636 LV_CELL_NTC_11_resistance "The resistance of the NTC #11 in the battery pack expressed in Ohm.";
CM_ SG_ 1636 LV_CELL_NTC_06_resistance "The resistance of the NTC #6 in the battery pack expressed in Ohm.";
CM_ BO_ 802 "(cycle_time: 10) (send_type: Cyclic)";
CM_ SG_ 802 LPPS_DAMPER_FL_voltage "The voltage of the linear potentiometer position sensor on the front left damper expressed in mV.";
CM_ SG_ 802 LPPS_DAMPER_FR_voltage "The voltage of the linear potentiometer position sensor on the front right damper expressed in mV.";
CM_ BO_ 646 "(send_type: CyclicIfActive)";
CM_ SG_ 646 xcp_payload "xcp payload data";
CM_ BO_ 1735 "(cycle_time: 200) (send_type: Cyclic)";
CM_ SG_ 1735 LED_4_color "Dashboard LED #4 color control.";
CM_ SG_ 1735 LED_1_color "Dashboard LED #1 color control.";
CM_ SG_ 1735 LED_2_color "Dashboard LED #2 color control.";
CM_ SG_ 1735 LED_3_color "Dashboard LED #3 color control.";
CM_ BO_ 1602 "(send_type: IfActive)";
CM_ SG_ 1602 FW_minorVersion "firmware minor version number";
CM_ SG_ 1602 FW_patchVersion "firmware patch version number";
CM_ SG_ 1602 FW_majorVersion "firmware major version number";
CM_ BO_ 82 "(cycle_time: 10) (send_type: Cyclic)";
CM_ SG_ 82 APPS_0_voltage "The voltage of the APPS #0 expressed in mV.";
CM_ SG_ 82 APPS_1_voltage "The voltage of the APPS #1 expressed in mV.";
CM_ SG_ 82 STEER_RME_voltage "The voltage of the Steering Wheel RME (rotary magnetic encoder) sensor expressed in mV.";
CM_ SG_ 82 BRAKE_PRESS_FRONT_voltage "The voltage of the front brake pressure sensor expressed in mV.";
CM_ BO_ 737 "(cycle_time: 10) (send_type: Cyclic)";
CM_ SG_ 737 SDC_PRCH_RLY_isClosed "States whether the SDC precharge relay is closed.";
CM_ BO_ 324 "(cycle_time: 100) (send_type: Cyclic)";
CM_ SG_ 324 LV_BAT_currentSensVoltage "The voltage returned by the current sensor of the LV battery expressed in mV.";
CM_ SG_ 324 LV_BAT_summedVoltage "The total voltage of the LV battery pack calculated by summing each cell voltage expressed in mV.";
CM_ SG_ 324 LV_BAT_voltage "The total read voltage of the LV battery pack expressed in mV.";
CM_ BO_ 1122 "(send_type: CyclicIfActive)";
CM_ SG_ 1122 xcp_payload "xcp payload data";
CM_ BO_ 1604 "(send_type: IfActive)";
CM_ SG_ 1604 FW_majorVersion "firmware major version number";
CM_ SG_ 1604 FW_minorVersion "firmware minor version number";
CM_ SG_ 1604 FW_patchVersion "firmware patch version number";
CM_ BO_ 1204 "(cycle_time: 100) (send_type: Cyclic)";
CM_ SG_ 1204 LV_CELL_2_isOV "States whether the LV cell #2 is in overvoltage.";
CM_ SG_ 1204 LV_CELL_NTC_09_isOT "States whether the LV cell temperature sensor #9 (NTC) detects an over temperature.";
CM_ SG_ 1204 LV_CELL_4_isUV "States whether the LV cell #4 is in undervoltage.";
CM_ SG_ 1204 LV_CELL_NTC_04_isOT "States whether the LV cell temperature sensor #4 (NTC) detects an over temperature.";
CM_ SG_ 1204 LV_CELL_NTC_05_isOT "States whether the LV cell temperature sensor #5 (NTC) detects an over temperature.";
CM_ SG_ 1204 LV_CELL_NTC_10_isOT "States whether the LV cell temperature sensor #10 (NTC) detects an over temperature.";
CM_ SG_ 1204 LV_CELL_6_isUV "States whether the LV cell #6 is in undervoltage.";
CM_ SG_ 1204 LV_CELL_1_isOV "States whether the LV cell #1 is in overvoltage.";
CM_ SG_ 1204 LV_CELL_1_isUV "States whether the LV cell #1 is in undervoltage.";
CM_ SG_ 1204 LV_CELL_2_isUV "States whether the LV cell #2 is in undervoltage.";
CM_ SG_ 1204 LV_CELL_5_isUV "States whether the LV cell #5 is in undervoltage.";
CM_ SG_ 1204 LV_CELL_6_isOV "States whether the LV cell #6 is in overvoltage.";
CM_ SG_ 1204 LV_CELL_NTC_02_isOT "States whether the LV cell temperature sensor #2 (NTC) detects an over temperature.";
CM_ SG_ 1204 LV_CELL_0_isOV "States whether the LV cell #0 is in overvoltage.";
CM_ SG_ 1204 LV_CELL_0_isUV "States whether the LV cell #0 is in undervoltage.";
CM_ SG_ 1204 LV_CELL_4_isOV "States whether the LV cell #4 is in overvoltage.";
CM_ SG_ 1204 LV_CELL_NTC_03_isOT "States whether the LV cell temperature sensor #3 (NTC) detects an over temperature.";
CM_ SG_ 1204 LV_CELL_NTC_00_isOT "States whether the LV cell temperature sensor #0 (NTC) detects an over temperature.";
CM_ SG_ 1204 LV_CELL_NTC_08_isOT "States whether the LV cell temperature sensor #8 (NTC) detects an over temperature.";
CM_ SG_ 1204 LV_CELL_NTC_11_isOT "States whether the LV cell temperature sensor #11 (NTC) detects an over temperature.";
CM_ SG_ 1204 LV_CELL_3_isOV "States whether the LV cell #3 is in overvoltage.";
CM_ SG_ 1204 LV_CELL_3_isUV "States whether the LV cell #3 is in undervoltage.";
CM_ SG_ 1204 LV_CELL_NTC_06_isOT "States whether the LV cell temperature sensor #6 (NTC) detects an over temperature.";
CM_ SG_ 1204 LV_CELL_NTC_07_isOT "States whether the LV cell temperature sensor #7 (NTC) detects an over temperature.";
CM_ SG_ 1204 LV_CELL_NTC_01_isOT "States whether the LV cell temperature sensor #1 (NTC) detects an over temperature.";
CM_ SG_ 1204 LV_CELL_5_isOV "States whether the LV cell #5 is in overvoltage.";
CM_ BO_ 1685 "(send_type: IfActive)";
CM_ SG_ 1685 APPS_1_voltageRangeMax "APPS channel #1 maximum range expressed in mV.";
CM_ SG_ 1685 APPS_1_voltageRangeMin "APPS channel #1 minimum range expressed in mV.";
CM_ SG_ 1685 APPS_0_voltageRangeMax "APPS channel #0 maximum range expressed in mV.";
CM_ SG_ 1685 APPS_0_voltageRangeMin "APPS channel #0 minimum range expressed in mV.";
CM_ BO_ 1650 "(cycle_time: 500) (send_type: Cyclic)";
CM_ SG_ 1650 SPARE_NTC_0_resistance "The resistance of the spare NTC #0 expressed in Ohm.";
CM_ SG_ 1650 SPARE_NTC_1_resistance "The resistance of the spare NTC #1 expressed in Ohm.";
CM_ SG_ 1650 COLDPLATE_L_NTC_resistance "The resistance of the left coldplate NTC expressed in Ohm.";
CM_ SG_ 1650 COLDPLATE_R_NTC_resistance "The resistance of the right coldplate NTC expressed in Ohm.";
CM_ SG_ 1650 JACKET_FL_NTC_resistance "The resistance of the front left jacket NTC expressed in Ohm.";
CM_ SG_ 1650 JACKET_FR_NTC_resistance "The resistance of the front right jacket NTC expressed in Ohm.";
CM_ BO_ 726 "(send_type: CyclicIfActive)";
CM_ SG_ 726 xcp_payload "xcp payload data";
CM_ BO_ 1220 "(cycle_time: 500) (send_type: Cyclic)";
CM_ SG_ 1220 LV_RELAY_isClosed "States whether the LV relay is closed.";
CM_ SG_ 1220 LV_RELAY_isRelayOverrideOn "States whether the LV relay override is enabled.";
CM_ BO_ 755 "(cycle_time: 10) (send_type: Cyclic)";
CM_ SG_ 755 SDC_POST_BSPD_isClosed "States whether the SDC post BSPD is closed.";
CM_ SG_ 755 SDC_PRE_PUSH_BTNS_isClosed "States whether the SDC per push buttons (hoop right/left) is closed.";
CM_ SG_ 755 SDC_POST_DC_BUS_isClosed "States whether the SDC post DC bus (inverter mono) is closed.";
CM_ SG_ 755 SDC_POST_INV_FR_isClosed "States whether the SDC post inverter front right is closed.";
CM_ BO_ 819 "(cycle_time: 10) (send_type: Cyclic)";
CM_ SG_ 819 LPPS_DAMPER_RR_voltage "The voltage of the linear potentiometer position sensor on the rear left damper expressed in mV.";
CM_ SG_ 819 LPPS_DAMPER_RL_voltage "The voltage of the linear potentiometer position sensor on the rear left damper expressed in mV.";
CM_ BO_ 1306 "(send_type: CyclicIfActive)";
CM_ SG_ 1306 TIRE_RR_temperature "The temperature of the rear right tire.";
CM_ SG_ 1306 TIRE_RL_pressure "The pressure of the rear left tire.";
CM_ SG_ 1306 TIRE_RL_sensID "The sensor id of the rear left tire.";
CM_ SG_ 1306 TIRE_RL_status "The status the rear left tire.";
CM_ SG_ 1306 TIRE_RL_temperature "The temperature of the rear left tire.";
CM_ SG_ 1306 TIRE_RR_pressure "The pressure of the rear right tire.";
CM_ SG_ 1306 TIRE_RR_sensID "The sensor id of the rear right tire.";
CM_ SG_ 1306 TIRE_RR_status "The status the rear right tire.";
CM_ BO_ 694 "(send_type: CyclicIfActive)";
CM_ SG_ 694 xcp_payload "xcp payload data";
CM_ BO_ 357 "(cycle_time: 500) (send_type: Cyclic)";
CM_ SG_ 357 ROT_SW_2_state "Rotary Switch 2 state";
CM_ SG_ 357 BTN_RTD_isPressed "Ready To Drive Button pressed.";
CM_ SG_ 357 BTN_1_isPressed "Steering wheel Button #1 is pressed.";
CM_ SG_ 357 BTN_2_isPressed "Steering wheel Button #2 is pressed.";
CM_ SG_ 357 BTN_3_isPressed "Steering wheel Button #3 is pressed.";
CM_ SG_ 357 BTN_4_isPressed "Steering wheel Button #4 is pressed.";
CM_ SG_ 357 ROT_SW_1_state "Rotary Switch 1 state";
CM_ BO_ 1607 "(send_type: IfActive)";
CM_ SG_ 1607 FW_majorVersion "firmware major version number";
CM_ SG_ 1607 FW_minorVersion "firmware minor version number";
CM_ SG_ 1607 FW_patchVersion "firmware patch version number";
CM_ BO_ 770 "(cycle_time: 10) (send_type: Cyclic)";
CM_ SG_ 770 SDC_POST_CP_PUSH_BTN_isActive "States whether the SDC post cockpit push button is active.";
CM_ SG_ 770 SDC_POST_INERTIA_isActive "States whether the SDC post inertia switch is active.";
CM_ SG_ 770 SDC_POST_BOTS_isActive "States whether the SDC post BOTS is active.";
CM_ BO_ 1121 "(send_type: CyclicIfActive)";
CM_ SG_ 1121 xcp_payload "xcp payload data";
CM_ BO_ 1290 "(send_type: CyclicIfActive)";
CM_ SG_ 1290 TIRE_FL_status "The status the front left tire.";
CM_ SG_ 1290 TIRE_FL_temperature "The temperature of the front left tire.";
CM_ SG_ 1290 TIRE_FR_pressure "The pressure of the front right tire.";
CM_ SG_ 1290 TIRE_FR_sensID "The sensor id of the front right tire.";
CM_ SG_ 1290 TIRE_FR_status "The status the front right tire.";
CM_ SG_ 1290 TIRE_FR_temperature "The temperature of the front right tire.";
CM_ SG_ 1290 TIRE_FL_pressure "The pressure of the front left tire.";
CM_ SG_ 1290 TIRE_FL_sensID "The sensor id of the front left tire.";
CM_ BO_ 1269 "(cycle_time: 500) (send_type: Cyclic)";
CM_ SG_ 1269 TSAC_FAN_pwmDutyCycleStatus "PWM duty cycle percentage for TSAC fans control.";
CM_ BO_ 99 "(cycle_time: 10) (send_type: Cyclic)";
CM_ SG_ 99 BRAKE_PRESS_REAR_voltage "The voltage of the rear brake pressure sensor expressed in mV.";
CM_ SG_ 99 COOL_PRESS_LEFT_voltage "The voltage of the left cooling pressure sensor expressed in mV.";
CM_ SG_ 99 COOL_PRESS_RIGHT_voltage "The voltage of the right cooling pressure sensor expressed in mV.";
CM_ BO_ 1129 "(send_type: CyclicIfActive)";
CM_ SG_ 1129 xcp_payload "xcp payload data";
CM_ BO_ 65 "(cycle_time: 10) (send_type: Cyclic)";
CM_ SG_ 65 DCBUS_PRECH_RLY_isClosed "Status of the DCBUS Precharge Relay mechanical state.";
CM_ SG_ 65 AIR_NEG_STG_mechStateSignal_isActive "States whether a Short To Gnd on AIR NEG mechanical state signal is active.";
CM_ SG_ 65 AIR_POS_STG_mechStateSignal_isActive "States whether a Short To Gnd on AIR POS mechanical state signal is active.";
CM_ SG_ 65 AIR_NEG_cmd_isActive "Status of the Negative AIR command.";
CM_ SG_ 65 AIR_NEG_isClosed "Status of the Negative AIR mechanical state.";
CM_ SG_ 65 DCBUS_PRECH_RLY_cmd_isActive "Status of the DCBUS Precharge Relay command.";
CM_ SG_ 65 AMS_errIsActive "States whether the AMS error is active.";
CM_ SG_ 65 DCBUS_isOver60V "States whether the DC BUS volatge is over 60V.";
CM_ SG_ 65 IMP_AIRs_Signals_isActive "States whether an implausibility on AIRs (NEG,POS) signals is active.";
CM_ SG_ 65 TSAL_green_isActive "States whether the TSAL green signal is active.";
CM_ SG_ 65 IMP_HV_Relays_Signals_isActive "States whether an implausibility on HV relays (NEG,POS,PRECH) signals is active.";
CM_ SG_ 65 AIR_POS_cmd_isActive "Status of the Positive AIR command.";
CM_ SG_ 65 AIR_POS_isClosed "Status of the Positive AIR mechanical state.";
CM_ SG_ 65 IMD_errIsActive "States whether the IMD error is active.";
CM_ SG_ 65 IMP_any_isActive "States whether any implausibility is active.";
CM_ BO_ 1175 "(cycle_time: 100) (send_type: Cyclic)";
CM_ SG_ 1175 HVBAT_soc "HV Battery State Of Charge percentage";
CM_ BO_ 1667 "(cycle_time: 500) (send_type: Cyclic)";
CM_ SG_ 1667 RAD_RL_OUT_NTC_resistance "The resistance of the rear left OUT radiator NTC expressed in Ohm.";
CM_ SG_ 1667 RAD_RR_IN_NTC_resistance "The resistance of the rear right IN radiator NTC expressed in Ohm.";
CM_ SG_ 1667 RAD_RR_OUT_NTC_resistance "The resistance of the rear right OUT radiator NTC expressed in Ohm.";
CM_ SG_ 1667 JACKET_RL_NTC_resistance "The resistance of the rear left jacket NTC expressed in Ohm.";
CM_ SG_ 1667 JACKET_RR_NTC_resistance "The resistance of the rear right jacket NTC expressed in Ohm.";
CM_ SG_ 1667 RAD_RL_IN_NTC_resistance "The resistance of the rear left IN radiator NTC expressed in Ohm.";
CM_ BO_ 1800 "IRTS message placeholder TODO: update this message when you have the specification";
CM_ BO_ 710 "(send_type: CyclicIfActive)";
CM_ SG_ 710 xcp_payload "xcp payload data";
CM_ BO_ 1603 "(send_type: IfActive)";
CM_ SG_ 1603 FW_minorVersion "firmware minor version number";
CM_ SG_ 1603 FW_patchVersion "firmware patch version number";
CM_ SG_ 1603 FW_majorVersion "firmware major version number";

BA_DEF_ BO_ "GenMsgCycleTime" INT 0 1000;
BA_DEF_ BO_ "GenMsgSendType" ENUM "NoMsgSendType","Cyclic","IfActive","CyclicIfActive","NotUsed";
BA_DEF_ SG_ "GenSigSendType" ENUM "NoSigSendType","Cyclic","OnWrite","OnWriteWithRepetition","OnChange","OnChangeWithRepetition","IfActive","IfActiveWithRepetition","NotUsed";
BA_DEF_DEF_ "GenMsgCycleTime" 0;
BA_DEF_DEF_ "GenMsgSendType" "NoMsgSendType";
BA_DEF_DEF_ "GenSigSendType" "NoSigSendType";
BA_ "GenMsgCycleTime" BO_ 357 500;
BA_ "GenMsgCycleTime" BO_ 1269 500;
BA_ "GenMsgCycleTime" BO_ 1252 100;
BA_ "GenMsgCycleTime" BO_ 1650 500;
BA_ "GenMsgCycleTime" BO_ 819 10;
BA_ "GenMsgCycleTime" BO_ 1667 500;
BA_ "GenMsgCycleTime" BO_ 1719 200;
BA_ "GenMsgCycleTime" BO_ 802 10;
BA_ "GenMsgCycleTime" BO_ 82 10;
BA_ "GenMsgCycleTime" BO_ 755 10;
BA_ "GenMsgCycleTime" BO_ 65 10;
BA_ "GenMsgCycleTime" BO_ 99 10;
BA_ "GenMsgCycleTime" BO_ 115 10;
BA_ "GenMsgCycleTime" BO_ 23 10;
BA_ "GenMsgCycleTime" BO_ 1191 100;
BA_ "GenMsgCycleTime" BO_ 1636 2000;
BA_ "GenMsgCycleTime" BO_ 737 10;
BA_ "GenMsgCycleTime" BO_ 1220 500;
BA_ "GenMsgCycleTime" BO_ 1236 100;
BA_ "GenMsgCycleTime" BO_ 407 100;
BA_ "GenMsgCycleTime" BO_ 1204 100;
BA_ "GenMsgCycleTime" BO_ 1175 100;
BA_ "GenMsgCycleTime" BO_ 1735 200;
BA_ "GenMsgCycleTime" BO_ 324 100;
BA_ "GenMsgCycleTime" BO_ 770 10;
BA_ "GenMsgCycleTime" BO_ 1620 2000;
BA_ "GenMsgSendType" BO_ 1204 1;
BA_ "GenMsgSendType" BO_ 357 1;
BA_ "GenMsgSendType" BO_ 99 1;
BA_ "GenMsgSendType" BO_ 1605 2;
BA_ "GenMsgSendType" BO_ 1191 1;
BA_ "GenMsgSendType" BO_ 1620 1;
BA_ "GenMsgSendType" BO_ 1719 1;
BA_ "GenMsgSendType" BO_ 1650 1;
BA_ "GenMsgSendType" BO_ 1220 1;
BA_ "GenMsgSendType" BO_ 65 1;
BA_ "GenMsgSendType" BO_ 1269 1;
BA_ "GenMsgSendType" BO_ 1175 1;
BA_ "GenMsgSendType" BO_ 115 1;
BA_ "GenMsgSendType" BO_ 1252 1;
BA_ "GenMsgSendType" BO_ 737 1;
BA_ "GenMsgSendType" BO_ 819 1;
BA_ "GenMsgSendType" BO_ 1607 2;
BA_ "GenMsgSendType" BO_ 1603 2;
BA_ "GenMsgSendType" BO_ 678 3;
BA_ "GenMsgSendType" BO_ 23 1;
BA_ "GenMsgSendType" BO_ 802 1;
BA_ "GenMsgSendType" BO_ 770 1;
BA_ "GenMsgSendType" BO_ 1121 3;
BA_ "GenMsgSendType" BO_ 1290 3;
BA_ "GenMsgSendType" BO_ 1701 2;
BA_ "GenMsgSendType" BO_ 726 3;
BA_ "GenMsgSendType" BO_ 755 1;
BA_ "GenMsgSendType" BO_ 1129 3;
BA_ "GenMsgSendType" BO_ 1125 3;
BA_ "GenMsgSendType" BO_ 407 1;
BA_ "GenMsgSendType" BO_ 1636 1;
BA_ "GenMsgSendType" BO_ 324 1;
BA_ "GenMsgSendType" BO_ 710 3;
BA_ "GenMsgSendType" BO_ 662 3;
BA_ "GenMsgSendType" BO_ 646 3;
BA_ "GenMsgSendType" BO_ 1735 1;
BA_ "GenMsgSendType" BO_ 1604 2;
BA_ "GenMsgSendType" BO_ 1685 2;
BA_ "GenMsgSendType" BO_ 1124 3;
BA_ "GenMsgSendType" BO_ 1123 3;
BA_ "GenMsgSendType" BO_ 1601 2;
BA_ "GenMsgSendType" BO_ 1602 2;
BA_ "GenMsgSendType" BO_ 1306 3;
BA_ "GenMsgSendType" BO_ 694 3;
BA_ "GenMsgSendType" BO_ 1667 1;
BA_ "GenMsgSendType" BO_ 1236 1;
BA_ "GenMsgSendType" BO_ 82 1;
BA_ "GenMsgSendType" BO_ 1122 3;

VAL_ 1735 LED_3_color 1 "RED" 4 "CYAN" 6 "MAGENTA" 8 "WHITE" 7 "YELLOW" 0 "BLACK" 2 "GREEN" 3 "BLUE" 5 "LIME";
VAL_ 1735 LED_4_color 0 "BLACK" 2 "GREEN" 3 "BLUE" 5 "LIME" 7 "YELLOW" 1 "RED" 4 "CYAN" 6 "MAGENTA" 8 "WHITE";
VAL_ 1735 LED_1_color 1 "RED" 4 "CYAN" 6 "MAGENTA" 8 "WHITE" 7 "YELLOW" 0 "BLACK" 2 "GREEN" 3 "BLUE" 5 "LIME";
VAL_ 1735 LED_2_color 3 "BLUE" 5 "LIME" 7 "YELLOW" 0 "BLACK" 2 "GREEN" 6 "MAGENTA" 8 "WHITE" 1 "RED" 4 "CYAN";
VAL_ 1191 DSPACE_main_FSM_State 1 "PRECHARGE" 2 "TS ON" 3 "RTD REQUEST" 4 "RTD" 5 "TS OFF" 255 "DISCHARGE" 0 "IDLE";
VAL_ 1191 DSPACE_amkInvFL_FSM_State 1 "LV ON " 2 "TS ON" 3 "RTD" 4 "MOTOR DRIVE" 5 "INTERM ERROR" 6 "HARD ERROR" 0 "RESET";
VAL_ 1191 DSPACE_amkInvFR_FSM_State 2 "TS ON" 3 "RTD" 4 "MOTOR DRIVE" 5 "INTERM ERROR" 6 "HARD ERROR" 0 "RESET" 1 "LV ON ";
VAL_ 1191 DSPACE_amkInvRL_FSM_State 5 "INTERM ERROR" 6 "HARD ERROR" 0 "RESET" 1 "LV ON " 2 "TS ON" 3 "RTD" 4 "MOTOR DRIVE";
VAL_ 1191 DSPACE_amkInvRR_FSM_State 6 "HARD ERROR" 0 "RESET" 1 "LV ON " 2 "TS ON" 3 "RTD" 4 "MOTOR DRIVE" 5 "INTERM ERROR";
